# channel_model: IP-XACT component
VLNV IcronTechnologies:IcronTechnologies:channel_model:1.0

## Parameters
addr_width = 8
bus_width = 32

## Bus interfaces (logical=physical port)
default_map: slave AGNISYS:AGNISYS:APB:1.0, memory map channelmap
  pclk=pclk, presetn=presetn, psel=psel, penable=penable, pwrite=pwrite, pprot=pprot, pstrb=pstrb, pwdata=pwdata, paddr=paddr, pready=pready, prdata=prdata, pslverr=pslverr

## Ports
in pclk
in presetn
in psel
in penable
in pwrite
in pprot[2:0]
in pstrb[(bus_width div 8 )-1:0]
in pwdata[bus_width -1:0]
in paddr[addr_width -1:0]
out pready
out prdata[bus_width -1:0]
out pslverr
out mca_channel_regscontrol0_enb
out mca_channel_regscontrol0_auto_reconnect_r
out mca_channel_regscontrol0_tx_en_r
out mca_channel_regscontrol0_rx_en_r
out mca_channel_regscontrol0_lnk_en_r
in mca_channel_regsstatus0_rx_rdy_in
in mca_channel_regsstatus0_rx_rdy_in_enb
in mca_channel_regsstatus0_tx_rdy_in
in mca_channel_regsstatus0_tx_rdy_in_enb
in mca_channel_regsstatus0_lnk_rdy_in
in mca_channel_regsstatus0_lnk_rdy_in_enb
in mca_channel_regsstatus0_ch_rdy_in
in mca_channel_regsstatus0_ch_rdy_in_enb
out mca_channel_regslink_control0_ltssm_enb
out mca_channel_regslink_control0_ltssm_crd_lmt_en_r
out mca_channel_regslink_control0_ltssm_pnd_lmt_en_r
out mca_channel_regslink_control0_ltssm_u0rectimeout_lmt_en_r
out mca_channel_regslink_control0_ltssm_u0ltimeout_lmt_en_r
out mca_channel_regslink_control0_ltssm_rec_idl_lmt_en_r
out mca_channel_regslink_control0_ltssm_rec_idl_rpt_en_r
out mca_channel_regslink_control0_ltssm_rec_act_rpt_en_r
out mca_channel_regslink_control0_ltssm_pol_idl_lmt_en_r
out mca_channel_regslink_control0_ltssm_pol_idl_rpt_en_r
out mca_channel_regslink_control0_ltssm_pol_act_rpt_en_r
out mca_channel_regslink_control0_test_enb
out mca_channel_regslink_control0_test_force_bad_lcrd_r
out mca_channel_regslink_control0_test_force_bad_lgood_r
out mca_channel_regslink_control0_test_force_bad_data_nrtry_r
out mca_channel_regslink_control0_test_force_bad_data_rtry_r
out mca_channel_regslink_control0_test_go2_recovery_r
out mca_channel_regslink_control0_test_dp_tx_hdr_ovrd_time_r
out mca_channel_regslink_control0_test_measure_latency_r
out mca_channel_regslink_stats0_rd2clr_config_rd_valid_out
out mca_channel_regslink_stats0_rd2clr_config_wr_valid_out
out mca_channel_regslink_stats0_u0_to_rec_rd_valid_out
out mca_channel_regslink_stats0_pol_fail_rd_valid_out
out mca_channel_regslink_stats0_tx_frm_rd_valid_out
out mca_channel_regslink_stats0_tx_mcup_rd_valid_out
out mca_channel_regslink_stats0_rx_frm_rd_valid_out
out mca_channel_regslink_stats0_rx_mcup_rd_valid_out
out mca_channel_regslink_stats0_latency_rd_valid_out
out mca_channel_regstx_control0_dp_enb
out mca_channel_regstx_control0_dp_mcup_pld_max_cycles_r[3:0]
out mca_channel_regstx_control0_dp_force_retry_r
out mca_channel_regstx_control0_dp_block_retry_r
out mca_channel_regstx_control0_dp_bw_src_r
out mca_channel_regstx_control0_dp_drp_on_pkt_err_r
out mca_channel_regstx_control0_dp_flw_ctrl_en_r
out mca_channel_regstx_control0_dp_hys_en_r
out mca_channel_regstx_control0_dp_drp_on_sop_r
out mca_channel_regstx_control0_rtry_buf_enb
out mca_channel_regstx_control0_rtry_buf_base_addr_r[31:0]
out mca_channel_regstx_control0_fifo_hys_enb
out mca_channel_regstx_control0_fifo_hys_hi_r[15:0]
out mca_channel_regstx_control0_fifo_hys_lo_r[15:0]
out mca_channel_regstx_control0_bandwidth_limit_enb
out mca_channel_regstx_control0_bandwidth_limit_hi_r[15:0]
out mca_channel_regstx_control0_bandwidth_limit_lo_r[15:0]
out mca_channel_regstx_stats0_rd2clr_config_rd_valid_out
out mca_channel_regstx_stats0_rd2clr_config_wr_valid_out
out mca_channel_regstx_stats0_cmd_fifo_rd_valid_out
out mca_channel_regstx_stats0_dp_pfifo_rd_valid_out
out mca_channel_regstx_stats0_dp_nfifo_rd_valid_out
out mca_channel_regstx_stats0_dp_fifo_rd_drp_pkt_rd_valid_out
out mca_channel_regstx_stats0_dp_fifo_wr_drp_pkt_rd_valid_out
out mca_channel_regstx_stats0_dp_fifo_wr_pkt_err_rd_valid_out
out mca_channel_regstx_stats0_dp_fifo_fifo_full_err_rd_valid_out
out mca_channel_regstx_stats0_dp_fifo_pkt_max_err_rd_valid_out
out mca_channel_regstx_stats0_dp_grd_no_sop_err_rd_valid_out
out mca_channel_regstx_stats0_dp_grd_no_eop_err_rd_valid_out
out mca_channel_regstx_stats0_dp_grd_max_err_rd_valid_out
out mca_channel_regstx_stats0_bandwidth_rd_valid_out
out mca_channel_regsrx_control0_dp_enb
out mca_channel_regsrx_control0_dp_hys_en_r
out mca_channel_regsrx_control0_dp_min_lvl_mode_r
out mca_channel_regsrx_control0_dp_drp_on_pkt_err_r
out mca_channel_regsrx_control0_dp_drp_on_sop_r
out mca_channel_regsrx_control0_dp_pkt_strm_r
out mca_channel_regsrx_control0_ntfy_mode_enb
out mca_channel_regsrx_control0_ntfy_mode_lmt_r[15:0]
out mca_channel_regsrx_control0_hys_lo_enb
out mca_channel_regsrx_control0_hys_lo_lvl_r[15:0]
out mca_channel_regsrx_control0_hys_hi_enb
out mca_channel_regsrx_control0_hys_hi_lvl_r[15:0]
out mca_channel_regsrx_stats0_rd2clr_config_rd_valid_out
out mca_channel_regsrx_stats0_rd2clr_config_wr_valid_out
out mca_channel_regsrx_stats0_dp_pfifo_rd_valid_out
out mca_channel_regsrx_stats0_dp_nfifo_rd_valid_out
out mca_channel_regsrx_stats0_dp_fifo_rd_drp_pkt_rd_valid_out
out mca_channel_regsrx_stats0_dp_fifo_wr_drp_pkt_rd_valid_out
out mca_channel_regsrx_stats0_dp_fifo_wr_pkt_err_rd_valid_out
out mca_channel_regsrx_stats0_dp_fifo_fifo_full_err_rd_valid_out
out mca_channel_regsrx_stats0_dp_fifo_pkt_max_err_rd_valid_out
out mca_channel_regsrx_stats0_dp_grd_no_sop_err_rd_valid_out
out mca_channel_regsrx_stats0_dp_grd_no_eop_err_rd_valid_out
out mca_channel_regsrx_stats0_dp_grd_max_err_rd_valid_out
out mca_channel_regstest_mode_tx_config0_iwg_cnt_enb
out mca_channel_regstest_mode_tx_config0_iwg_cnt_setting_r[10:0]
out mca_channel_regstest_mode_tx_config0_ifg_cnt_enb
out mca_channel_regstest_mode_tx_config0_ifg_cnt_setting_r[10:0]
out mca_channel_regstest_mode_tx_config0_pkt_cnt_enb
out mca_channel_regstest_mode_tx_config0_pkt_cnt_setting_r[10:0]
out mca_channel_regstest_mode_tx_config0_pkt_size_enb
out mca_channel_regstest_mode_tx_config0_pkt_size_setting_r[10:0]
out mca_channel_regstest_mode_tx_config0_ctrl0_enb
out mca_channel_regstest_mode_tx_config0_ctrl0_random_r
out mca_channel_regstest_mode_tx_config0_ctrl0_throttle_r
out mca_channel_regstest_mode_tx_config0_ctrl0_mode_r
out mca_channel_regstest_mode_tx_config0_ctrl0_enable_r
out mca_channel_regstest_mode_tx_config0_ctrl0_go_r
out mca_channel_regstest_mode_tx_stats0_rd2clr_config_rd_valid_out
out mca_channel_regstest_mode_tx_stats0_rd2clr_config_wr_valid_out
out mca_channel_regstest_mode_tx_stats0_wait_count_rd_valid_out
out mca_channel_regstest_mode_tx_stats0_pkt_count_rd_valid_out
out mca_channel_regstest_mode_rx_config0_mgen_enb
out mca_channel_regstest_mode_rx_config0_mgen_en_rxflw_r
out mca_channel_regstest_mode_rx_config0_mgen_mode_r
out mca_channel_regstest_mode_rx_config0_mgen_enable_r
out mca_channel_regstest_mode_rx_config0_mgen_go_r
out mca_channel_regstest_mode_rx_stats0_rd2clr_config_rd_valid_out
out mca_channel_regstest_mode_rx_stats0_rd2clr_config_wr_valid_out
out mca_channel_regstest_mode_rx_stats0_err_count_rd_valid_out
out mca_channel_regstest_mode_rx_stats0_pkt_count_rd_valid_out

## Address spaces and blocks
channelmap.channel: base 0x000, range 0x100, width 32

## Registers
Registers are 32-bit, read-only, reset 0x0 unless marked. A register's access mark holds for its fields unless they carry their own. Offsets are from the block's base; lines under a group give offsets from that group; [hi:lo] are bit positions; {n}, {i} and the like mark numbered series; 'fields as' and 'values as' point back to an identical list; <NAME> marks a mode.

## channelmap.channel — MCA Channel register control
Base 0x00000000
0x00 version reset 0x10204
  [23:16] major — Major version
  [15:8] minor — Minor version
  [7:0] patch — Patch version
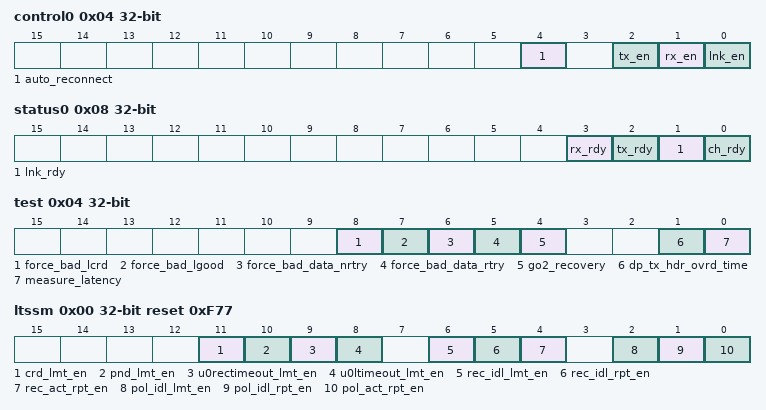
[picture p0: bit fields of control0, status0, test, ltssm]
0x04 control0 rw
  [4] auto_reconnect — When this bit is set it will allow the link to automatically establish a new connection after it detects the remote port has disconnected. 0-disable 1-enable
  [2] tx_en — Allows the TX logic to initialize and prepare for the movement of data between the local and remote port. After the port is initialized and capable of processing a corresponding ready bit will be set in the status0 register indicating so. 0 - Places the transmit data-path into a disable state. This state is used to 1 - Enables the transmit data-path for the local channel to initialize and prepare to move data.
  [1] rx_en — Allows the RX logic to initialize and prepare for the movement of data from the MCA to the application. After the port is initialized and capable of processing data a corresponding ready bit will be set in the status register indicating so. 0 - Forces RX logic into a disabled state 1 - Allows the RX logic to initialize and enter a state where data can be processed.
  [0] lnk_en — This register bit enables the link to establish a virtual connection to its remote ends (i.e. enables the LTSSM). This does not rely on the RX or TX components of the channel to be enabled. Upon connection a corresponding status bit will be set indicating that the logic connection has been established. 0 - Forces the channel into the disabled state 1 = Enables the link to establish a connection to the far end.
0x08 status0
  [3] rx_rdy — Indicates the channel RX logic is ready to process data.
  [2] tx_rdy — Indicates the channel TX logic is ready to process data.
  [1] lnk_rdy — This indicates that the LINK has entered U0 mode and the data-path is able to move data.
  [0] ch_rdy — Indicates that the link, RX, and TX components of the channel are in a state which will allow client data exchange.
0x0C link group — This register group contains channel based link management controls and status information.
  0x00 control0 group
    0x00 ltssm rw reset 0xF77 — This register manages the LTSSM
      [11] crd_lmt_en — Disables the credit pending timer. 0-disable 1-enable
      [10] pnd_lmt_en — Disables the U0 packet pending timer. 0-disable 1-enable
      [9] u0rectimeout_lmt_en — Disables the activity timer when in U0. 0-disable 1-enable
      [8] u0ltimeout_lmt_en — Timer used to generate link up broadcasts 0-disable 1-enable
      [6] rec_idl_lmt_en — Master recovery completion timer. 0-disable 1-enable
      [5] rec_idl_rpt_en — Recovery idle repeat timer. 0-disable 1-enable
      [4] rec_act_rpt_en — Disables the recovery active repeat timer. 0-disable 1-enable
      [2] pol_idl_lmt_en — Disables the master polling completion timer. 0-disable 1-enable
      [1] pol_idl_rpt_en — Disables the polling idle repeat timer. 0-disable 1-enable
      [0] pol_act_rpt_en — Disables the polling active repeat timer. 0-disable 1-enable
    0x04 test rw — This register manages the LTSSM
      [8] force_bad_lcrd — This bit forces the link to treat the next received lcrd command as if it were received in error.
      [7] force_bad_lgood — This bit forces the link to treat the next received lgood command as if it were received in error.
      [6] force_bad_data_nrtry — This bit forces the link receiver to treat the next non retriable packet as if it was received in error.
      [5] force_bad_data_rtry — This bit forces the link receiver to treat the next retriable packet as if it was received in error.
      [4] go2_recovery — This bit forces the local LTSSM into a recovery action. This is intended for lab testing. This bit is cleared as soon as the LTSSM enters the recovery state.
      [1] dp_tx_hdr_ovrd_time — This bit controls where the system time stamp is inserted at. 1 - At the final stage before the output of the MCA.TX to the link. 0- At the arbitration input
      [0] measure_latency — Enables the round trip latency transactions protocol for this channel.
  0x08 status0 group
    0x00 ltssm — Current State for LTSSM.
      [6] rec_idl — This port indicates that the ports are resynchronized and they are ready to enter back to U0.
      [5] rec_act — Indicates the port is in recovery and is waiting for the remote end to acknowledge the recovery action.
      [4] u0 — Indicates that the port is now in operating state where application data can be transmitted between the two ports.
      [3] pol_idl — This bit indicates that the LTSSM has found the far end port and is waiting for the far end port to acknowledge that it has discovered this port.
      [2] pol_act — This bit indicates the link is in the polling state. Polling is a discovery of the existence of a remote port.
      [1] dis — Indicates the LTSSM is in state disable. This is the default state from reset. As soon as software sets the link enable bit this state will transition to polling active.
      [0] inact — When in the inactive state software must clear the link enable bit and only enable it once the dis bit is set. This state is entered if the far end is disabled and re-enabled (i.e. entered polling) or if the recovery action timed out instead of completing the action.
  0x0C stats0 group
    0x00 rd2clr_config rw — Configures if the stats register read by s/w clears the read register. A 1 in any bit configures the h/w to clear the corresponding stats register after a s/w read of that stats register.
      [6] latency, [5] rx_mcup, [4] rx_frm, [3] tx_mcup, [2] tx_frm, [1] pol_fail, [0] u0_to_rec
    0x04 u0_to_rec — This register keeps track of the number of times the LTSSM state enters recovery from u0. This is not an error condition as much as it is a indication of general link health.
      [15:0] cnt
    0x08 pol_fail — This registers counts the number of times polling failed to get a idle response after detecting a remote training packet (resulting in the return to polling)
      [15:0] cnt
    0x0C tx_frm — This counts the application side packets being transmitted through the channel
      [31:0] cnt
    0x10 tx_mcup — This counts the number of MCUP's transmitted due to transmitting the application data
      [31:0] cnt
    0x14 rx_frm — This counts the application side packets being transmitted through the channel
      [31:0] cnt
    0x18 rx_mcup — This counts the number of MCUP's transmitted due to transmitting the application data
      [31:0] cnt
    0x1C latency — This reports the high water mark for the round trip latency measurement
      [31:0] cnt
0x38 tx group
  0x00 control0 group
    0x00 dp rw reset 0x80000
      [19:16] mcup_pld_max_cycles — This indicates the maximum size an MCUP payload will be limited to. The MCUP size is calculated as follows: (bytes_per_clock_cycle*mcup_pld_max_size)+(bytes_per_clock_cycle-mcup_header_size) eg. for 8 bytes per clock cycle, and a header size of 4 bytes, and a default value of 8: (8*8)+(8-4) = 68
      [13] force_retry — This bit will force the channel to support the retry behavior on all its packets. This bit overrides the block_retry bit.
      [12] block_retry — This bit will prevent all packets transmitted on this channel from supporting the retry behavior.
      [8] bw_src — Bandwidth measurements are derived before the fragmentation (i.e. raw bandwidth) or after the fragmentation logic.
      [5] drp_on_pkt_err — If a packet error is received during the notification point this bit will cause the FIFO to drop the packet.
      [4] flw_ctrl_en — Used to enable or disable flow control from the TX FIFO.
      [1] hys_en — If this is set the hysteresis flag will be set or cleared based on the FIFO depth.
      [0] drp_on_sop — 1 - All packets will be dropped at the input of the FIFO 0 - Normal operation
    0x04 rtry_buf rw — Retry buffer base address
      [31:0] base_addr — This register sets the base address for the channels retry buffer.
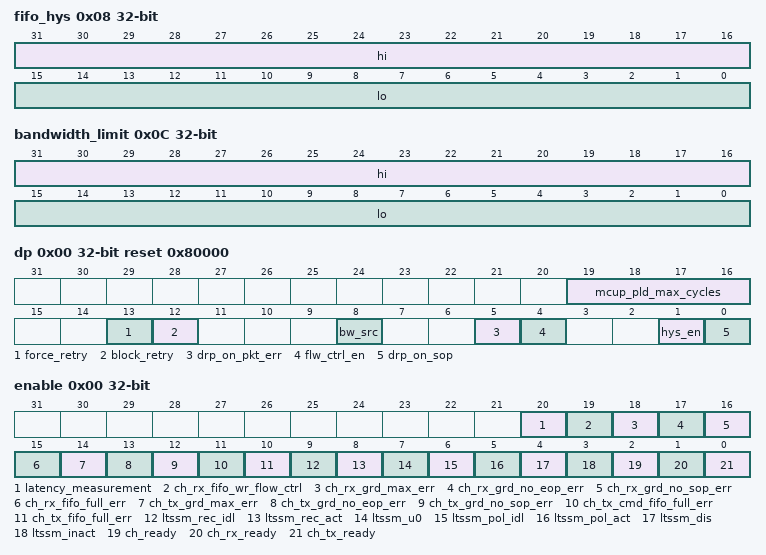
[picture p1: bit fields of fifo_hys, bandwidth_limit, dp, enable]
    0x08 fifo_hys rw
      [31:16] hi — Sets the upper FIFO level at which the hysteresis will be set. This value is based on FIFO words and not bytes.
      [15:0] lo — Sets the lower FIFO level at which the hysteresis will be cleared. This value is based on FIFO words and not bytes.
    0x0C bandwidth_limit rw — This register defines the bandwidth range which the channel can consume. If the upper range is exceeded then the channel will enter a flow control state until the bandwidth usage drops below the lo threshold. To disable bandwidth controls set the high register to 0xffff, and the lower register to 0x0000. Example: If bandwidth sample timer has a period of 256 core clock cycles the maximum number of bytes transmitted is 256 * 8bytes = 2048bytes (64 bit architecture in the core). If the hi register is set for 1536 this means a bandwidth which is greater than 1536/2048 =75% of the maximum bandwidth (10G with a clock of 6.4ns) will force the channel into a flow control condition. If the lower threshold is 1434 then the ratio is 1434/2048 which is approximately = 0.70 or 70% of the maximum bandwidth. When the bandwidth drops below this value then the flow control condition will be disabled. *Note the bandwidth is the ratio of the number of bytes transmitted during a sample period divided by the maximum number of bytes which could be transmitted during the same period.
      [31:16] hi — Sets the upper limit on the bandwidth operating range. This is used to limit the channels bandwidth consumption. Values of bandwidth which exceed this value will cause the transmit flow control mechanism for this channel to be asserted.
      [15:0] lo — Sets the lower limit on the bandwidth operating range. This is used to limit the channels bandwidth consumption. Values of bandwidth which drop below this value will cause the transmit flow control mechanism for this channel to be de-asserted.
  0x10 stats0 group — All the Statistic Registers and their configuration for the Write Engine
    0x00 rd2clr_config rw — Configures if the stats register read by s/w clears the read register. A 1 in any bit configures the h/w to clear the corresponding stats register after a s/w read of that stats register.
      [11] bandwidth, [10] dp_grd_max_err, [9] dp_grd_eop_err, [8] dp_grd_no_sop_err, [7] dp_fifo_pkt_max_err, [6] dp_fifo_fifo_full_err, [5] dp_fifo_wr_pkt_err, [4] dp_fifo_wr_drp_pkt, [3] dp_fifo_rd_drp_pkt, [2] dp_nfifo, [1] dp_pfifo, [0] cmd_fifo
    0x04 cmd_fifo — TX Command FIFO - This FIFO contains link commands (derived from link protocol responses/actions)
      [7:0] cnt
    0x08 dp_pfifo — Packet FIFO level. This represents the data for all the packets held in the FIFO subsystem.
      [31:0] cnt
    0x0C dp_nfifo — Notification FIFO level. This represents the number of packets in the FIFO subsystem.
      [31:0] cnt
    0x10 dp_fifo_rd_drp_pkt — Indicates the number of times a packet has been dropped at the read side of the receive FIFO.
      [7:0] cnt
    0x14 dp_fifo_wr_drp_pkt — The write side of the FIFO has dropped the application packet
      [7:0] cnt
    0x18 dp_fifo_wr_pkt_err — Indicates the packet was written into the FIFO which was received with the error flag set during the notify condition.
      [7:0] cnt
    0x1C dp_fifo_fifo_full_err — When flow control is disabled this indicates that the FIFO had reached its full point. If this happens during a packet it will be truncated and the error flag asserted with the EOP flag.
      [7:0] cnt
    0x20 dp_fifo_pkt_max_err
      [7:0] cnt
    0x24 dp_grd_no_sop_err — This Error indicates that MCUP data after and EOP is being transmitted.
      [7:0] cnt
    0x28 dp_grd_no_eop_err — This error indicates that there was an EOP missing between two SOP's.
      [7:0] cnt
    0x2C dp_grd_max_err — This error indicates that the MCUP exceeded the maximum MCUP packet size (i.e. 64bytes).
      [7:0] cnt
    0x30 bandwidth — This register reports the high level watermark of the channels bandwidth.
      [31:0] cnt
0x7C rx group
  0x00 control0 group
    0x00 dp rw
      [5] hys_en — Enables a hysteresis flag to operate based on the write side FIFO count.
      [4] min_lvl_mode — When in this mode the FIFO will not indicate there is data in the FIFO until the minimum level of data or EOP is written into the FIFO. The FIFO will continue to transmit until the FIFO is emptied at which point it will not start transmitting again until the FIFO has been filled back up to the minimum level again.
      [3] drp_on_pkt_err — If a packet error is received during the notification point this bit will cause the FIFO to drop the packet at the read engine.
      [2] drp_on_sop — Prevents all application packets from being written into the FIFO.
      [1] pkt_strm — 1-packet mode. The data is not provided to the destination until the EOP is written into the FIFO 0-Streaming mode. The data is not provided to the destination until the ntfy_mode register value (in bytes) has been written into the FIFO
    0x04 ntfy_mode rw
      [15:0] lmt — Depending on the mode of the FIFO two options can be set. Minimum level mode (number of FIFO words) Packet/Streaming mode (number of BYTES) The two modes cannot operate at the same time so this register is used for both controls.
    0x08 hys_lo rw
      [15:0] lvl — Sets the lower FIFO level at which the hysteresis will be cleared. This value is based on FIFO words and not bytes.
    0x0C hys_hi rw
      [15:0] lvl — Sets the upper FIFO level at which the hysteresis will be set. This value is based on FIFO words and not bytes.
  0x10 stats0 group — All the Statistic Registers and their configuration for the Write Engine
    0x00 rd2clr_config rw — Configures if the stats register read by s/w clears the read register. A 1 in any bit configures the h/w to clear the corresponding stats register after a s/w read of that stats register.
      [10] dp_grd_max_err, [9] dp_grd_eop_err, [8] dp_grd_no_sop_err, [7] dp_fifo_pkt_max_err, [6] dp_fifo_fifo_full_err, [5] dp_fifo_wr_pkt_err, [4] dp_fifo_wr_drp_pkt_wr, [3] dp_fifo_rd_drp_pkt, [1] dp_nfifo, [0] dp_pfifo
    0x04 dp_pfifo — Packet FIFO level. This represents the data for all the packets held in the FIFO subsystem.
      [31:0] cnt
    0x08 dp_nfifo — Notification FIFO level. This represents the number of packets in the FIFO subsystem.
      [31:0] cnt
    0x0C dp_fifo_rd_drp_pkt — Indicates the number of times a packet has been dropped at the read side of the receive FIFO.
      [7:0] cnt
    0x10 dp_fifo_wr_drp_pkt — The write side of the FIFO has dropped the application packet
      [7:0] cnt
    0x14 dp_fifo_wr_pkt_err — Indicates the packet was written into the FIFO which was received with the error flag set during the notify condition.
      [7:0] cnt
    0x18 dp_fifo_fifo_full_err — When flow control is disabled this indicates that the FIFO had reached its full point. If this happens during a packet it will be truncated and the error flag asserted with the EOP flag.
      [7:0] cnt
    0x1C dp_fifo_pkt_max_err — Indicates that the max size packet was written into the FIFO.
      [7:0] cnt
    0x20 dp_grd_no_sop_err — This Error indicates that MCUP data after and EOP is being transmitted.
      [7:0] cnt
    0x24 dp_grd_no_eop_err — This error indicates that there was an EOP missing between two SOP's.
      [7:0] cnt
    0x28 dp_grd_max_err — This error indicates that the MCUP exceeded the maximum MCUP packet size (i.e. 64bytes).
      [7:0] cnt
0xB8 irq0 group — MCA channel interrupts
  0x00 enable rw — Interrupt Enable register - Write 1 to enable, 0 to mask an interrupt
    [20] latency_measurement, [19] ch_rx_fifo_wr_flow_ctrl, [18] ch_rx_grd_max_err, [17] ch_rx_grd_no_eop_err, [16] ch_rx_grd_no_sop_err, [15] ch_rx_fifo_full_err, [14] ch_tx_grd_max_err, [13] ch_tx_grd_no_eop_err, [12] ch_tx_grd_no_sop_err, [11] ch_tx_cmd_fifo_full_err, [10] ch_tx_fifo_full_err, [9] ltssm_rec_idl, [8] ltssm_rec_act, [7] ltssm_u0, [6] ltssm_pol_idl, [5] ltssm_pol_act, [4] ltssm_dis, [3] ltssm_inact, [2] ch_ready, [1] ch_rx_ready, [0] ch_tx_ready
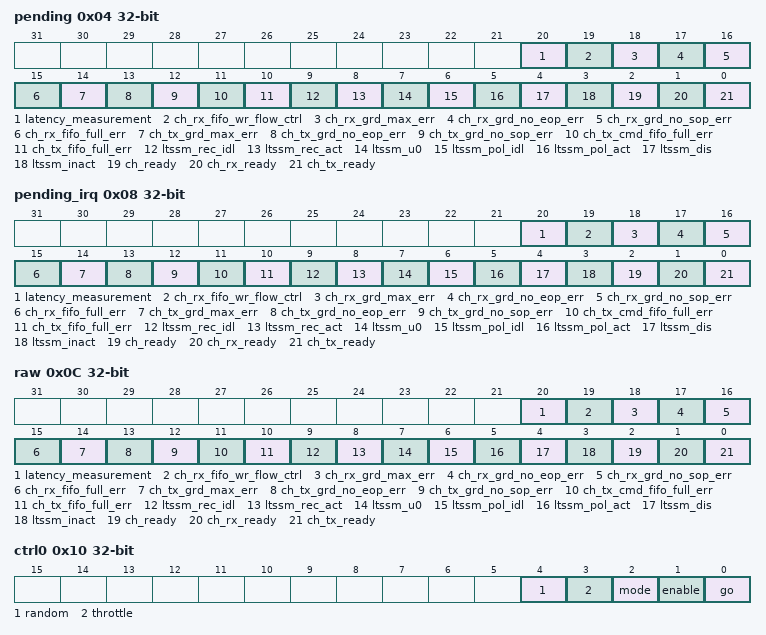
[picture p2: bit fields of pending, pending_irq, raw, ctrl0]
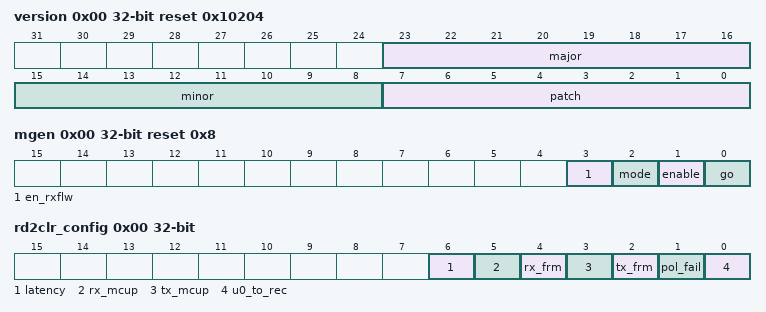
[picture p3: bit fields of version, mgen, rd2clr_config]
  0x04 pending rw — Interrupt Pending register - This indicates which enabled interrupts source been occurred. Only generates an interrupt when the corresponding enable bit is set. Write 1 to clear.
    [20] latency_measurement write-1-clears — Edge-triggered - Rising Edge
    [19] ch_rx_fifo_wr_flow_ctrl write-1-clears — Edge-triggered - Rising Edge
    [18] ch_rx_grd_max_err write-1-clears — Edge-triggered - Rising Edge
    [17] ch_rx_grd_no_eop_err write-1-clears — Edge-triggered - Rising Edge
    [16] ch_rx_grd_no_sop_err write-1-clears — Edge-triggered - Rising Edge
    [15] ch_rx_fifo_full_err write-1-clears — Edge-triggered - Rising Edge
    [14] ch_tx_grd_max_err write-1-clears — Edge-triggered - Rising Edge
    [13] ch_tx_grd_no_eop_err write-1-clears — Edge-triggered - Rising Edge
    [12] ch_tx_grd_no_sop_err write-1-clears — Edge-triggered - Rising Edge
    [11] ch_tx_cmd_fifo_full_err write-1-clears — Edge-triggered - Rising Edge
    [10] ch_tx_fifo_full_err write-1-clears — Edge-triggered - Rising Edge
    [9] ltssm_rec_idl write-1-clears — Edge-triggered - Rising Edge
    [8] ltssm_rec_act write-1-clears — Edge-triggered - Rising Edge
    [7] ltssm_u0 write-1-clears — Edge-triggered - Rising Edge
    [6] ltssm_pol_idl write-1-clears — Edge-triggered - Rising Edge
    [5] ltssm_pol_act write-1-clears — Edge-triggered - Rising Edge
    [4] ltssm_dis write-1-clears — Edge-triggered - Rising Edge
    [3] ltssm_inact write-1-clears — Edge-triggered - Rising Edge
    [2] ch_ready write-1-clears — Edge-triggered - Rising and Falling Edge
    [1] ch_rx_ready write-1-clears — Edge-triggered - Rising and Falling Edge
    [0] ch_tx_ready write-1-clears — Edge-triggered - Rising and Falling Edge
  0x08 pending_irq — Interrupt Pending register - This indicates which enabled interrupts have been triggered, Write 1 to clear
    [20] latency_measurement — Edge-triggered - Rising Edge
    [19] ch_rx_fifo_wr_flow_ctrl — Edge-triggered - Rising Edge
    [18] ch_rx_grd_max_err — Edge-triggered - Rising Edge
    [17] ch_rx_grd_no_eop_err — Edge-triggered - Rising Edge
    [16] ch_rx_grd_no_sop_err — Edge-triggered - Rising Edge
    [15] ch_rx_fifo_full_err — Edge-triggered - Rising Edge
    [14] ch_tx_grd_max_err — Edge-triggered - Rising Edge
    [13] ch_tx_grd_no_eop_err — Edge-triggered - Rising Edge
    [12] ch_tx_grd_no_sop_err — Edge-triggered - Rising Edge
    [11] ch_tx_cmd_fifo_full_err — Edge-triggered - Rising Edge
    [10] ch_tx_fifo_full_err — Edge-triggered - Rising Edge
    [9] ltssm_rec_idl — Edge-triggered - Rising Edge
    [8] ltssm_rec_act — Edge-triggered - Rising Edge
    [7] ltssm_u0 — Edge-triggered - Rising Edge
    [6] ltssm_pol_idl — Edge-triggered - Rising Edge
    [5] ltssm_pol_act — Edge-triggered - Rising Edge
    [4] ltssm_dis — Edge-triggered - Rising Edge
    [3] ltssm_inact — Edge-triggered - Rising Edge
    [2] ch_ready — Edge-triggered - Rising and Falling Edge
    [1] ch_rx_ready — Edge-triggered - Rising and Falling Edge
    [0] ch_tx_ready — Edge-triggered - Rising and Falling Edge
  0x0C raw — This register contains the active state of interrupt sources
    [20] latency_measurement — (Pulsed high) - Test Information ready
    [19] ch_rx_fifo_wr_flow_ctrl — (Active-High) - critical information
    [18] ch_rx_grd_max_err — (Pulsed High) - critical information
    [17] ch_rx_grd_no_eop_err — (Pulsed High) - critical information
    [16] ch_rx_grd_no_sop_err — (Pulsed High) - critical information
    [15] ch_rx_fifo_full_err — (Pulsed High) - critical information
    [14] ch_tx_grd_max_err — (Pulsed High) - critical information
    [13] ch_tx_grd_no_eop_err — (Pulsed High) - critical information
    [12] ch_tx_grd_no_sop_err — (Pulsed High) - critical information
    [11] ch_tx_cmd_fifo_full_err — (Pulsed High) - critical information
    [10] ch_tx_fifo_full_err — (Pulsed High) - critical information
    [9] ltssm_rec_idl — (Active-High) - Status Information
    [8] ltssm_rec_act — (Active-High) - Status Information
    [7] ltssm_u0 — (Active-High) - Status Information
    [6] ltssm_pol_idl — (Active-High) - Status Information
    [5] ltssm_pol_act — (Active-High) - Status Information
    [4] ltssm_dis — (Active-High) - Status Information
    [3] ltssm_inact — (Active-High) - Status Information
    [2] ch_ready — (Active-High) - Status Information
    [1] ch_rx_ready — (Active-High) - Status Information
    [0] ch_tx_ready — (Active-High) - Status Information
0xC8 test_mode group
  0x00 tx group — Registers needed for the Media Generator needed for self-test
    0x00 version reset 0x20000
      fields as version
    0x04 config0 group
      0x00 iwg_cnt rw — inter word gap count
        [10:0] setting — Media generator inter-word gap count. This is the number of srdy "not ready" (srdy = 1'b0) cycles that can be inserted between words. 0 = 0 cycles 1 = 1 cycle 2 = 2 cycles ect..
      0x04 ifg_cnt rw reset 0x1 — inter frame gap count
        [10:0] setting — Media generator inter-frame gap count. This is the number of clock cycles that can be inserted between packets. 0 = 0 cycles 1 = 1 cycle 2 = 2 cycles ect..
      0x08 pkt_cnt rw reset 0xA — number of packets to send
        [10:0] setting — Media generator packet count select. Set to "0" for continuous transmission mode.
      0x0C pkt_size rw reset 0x1 — packet length size in number of bytes
        [10:0] setting — Media generator packet length size in number of bytes
      0x10 ctrl0 rw — Media generator configuration register
        [4] random — Randomization of the following register control setting (internally driven) iwg_cnt ifg_cnt pkt_size 0 = disabled
        [3] throttle — Media generator throttle enable. Allows CPU to control media generator transmitter source ready (srdy). 0 = srdy with/without drdy (may cause loss of traffic) 1 = srdy with drdy
        [2] mode — Media generator "data" traffic mode select. 0 = incrementing data 1 = random data
        [1] enable — Media generator enable. Must be set '0' if the corresponding media is trying to connect to the pipe. Can also be set '0' to stop a media generator that is set for continuous transmission mode. Actual transmission will not start until the go bit is hit (ie: first enable then hit go bit). 0 = disabled 1 = enabled
        [0] go — Go/Busy (Cleared by HW) write: 0 = disabled 1 = start of test read: 0 = test complete 1 = test is running
    0x18 stats0 group — All the Statistic Registers and their configuration for the mgen_tx
      0x00 rd2clr_config rw — Configures if the stats register read by s/w clears the read register. A 1 in any bit configures the h/w to clear the corresponding stats register after a s/w read of that stats register.
        [1] wait_count, [0] pkt_count
      0x04 wait_count — Transmit wait count of destination not ready (drdy)
      0x08 pkt_count — Transmit packet count
  0x24 rx group — Registers needed for the Media Generator needed for self-test
    0x00 version reset 0x10000
      fields as version
    0x04 config0 group
      0x00 mgen rw reset 0x8 — Media generator configuration register
        [3] en_rxflw — Receiver drdy ready (flow control) 0 = drdy receiver not ready 1 = drdy receiver ready
        [2] mode — Media generator traffic mode select. 0 = incrementing data 1 = random data
        [1] enable — Media generator enable. Must be set '0' if the corresponding media is trying to connect to the pipe. Can also be set '0' to stop a media generator that is set for continuous mode. Set '1' if setting go '1'. 0 = disabled 1 = enabled
        [0] go — *Not implemented (expected possible future use)* Go/Busy (Cleared by HW)
    0x08 stats0 group — All the Statistic Registers and their configuration for the mgen_rx
      0x00 rd2clr_config rw — Configures if the stats register read by s/w clears the read register. A 1 in any bit configures the h/w to clear the corresponding stats register after a s/w read of that stats register.
        [1] err_count, [0] pkt_count
      0x04 err_count — Receive error count
      0x08 pkt_count — Receive packet count
